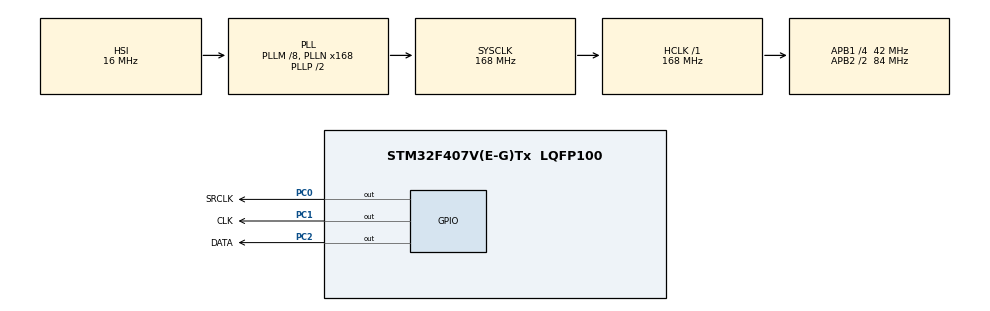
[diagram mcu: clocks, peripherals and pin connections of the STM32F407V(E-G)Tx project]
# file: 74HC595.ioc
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Mcu.Family=STM32F4
Mcu.Name=STM32F407V(E-G)Tx
Mcu.Package=LQFP100
NVIC.PriorityGroup=NVIC_PRIORITYGROUP_4
PA13.Mode=Serial_Wire
PA13.Signal=SYS_JTMS-SWDIO
PA14.Mode=Serial_Wire
PA14.Signal=SYS_JTCK-SWCLK
PC0.GPIO_Label=SRCLK
PC0.GPIO_Speed=GPIO_SPEED_FREQ_HIGH
PC0.Signal=GPIO_Output
PC1.GPIO_Label=CLK
PC1.GPIO_Speed=GPIO_SPEED_FREQ_HIGH
PC1.Signal=GPIO_Output
PC2.GPIO_Label=DATA
PC2.GPIO_Speed=GPIO_SPEED_FREQ_HIGH
PC2.Signal=GPIO_Output
PH0-OSC_IN.Mode=HSE-External-Oscillator
PH0-OSC_IN.Signal=RCC_OSC_IN
PH1-OSC_OUT.Mode=HSE-External-Oscillator
PH1-OSC_OUT.Signal=RCC_OSC_OUT
ProjectManager.HeapSize=0x200
ProjectManager.StackSize=0x400
ProjectManager.TargetToolchain=MDK-ARM V5
RCC.48MHZClocksFreq_Value=84000000
RCC.AHBFreq_Value=168000000
RCC.APB1CLKDivider=RCC_HCLK_DIV4
RCC.APB1Freq_Value=42000000
RCC.APB1TimFreq_Value=84000000
RCC.APB2CLKDivider=RCC_HCLK_DIV2
RCC.APB2Freq_Value=84000000
RCC.APB2TimFreq_Value=168000000
RCC.CortexFreq_Value=168000000
RCC.HCLKFreq_Value=168000000
RCC.HSE_VALUE=8000000
RCC.HSICalibrationValue=8
RCC.HSI_VALUE=16000000
RCC.LSE_VALUE=32768
RCC.PLLM=8
RCC.PLLN=168
RCC.SYSCLKFreq_VALUE=168000000
RCC.SYSCLKSource=RCC_SYSCLKSOURCE_PLLCLK
RCC.VCOOutputFreq_Value=336000000
board=custom

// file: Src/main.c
/* USER CODE BEGIN Header */
/**
  ******************************************************************************
  * @file           : main.c
  * @brief          : Main program body
  ******************************************************************************
  * @attention
  *
  * <h2><center>&copy; Copyright (c) 2019 STMicroelectronics.
  * All rights reserved.</center></h2>
  *
  * This software component is licensed by ST under BSD 3-Clause license,
  * the "License"; You may not use this file except in compliance with the
  * License. You may obtain a copy of the License at:
  *                        opensource.org/licenses/BSD-3-Clause
  *
  ******************************************************************************
  */
/* USER CODE END Header */

#include "main.h"

/* USER CODE BEGIN Includes */
#include "74hc595.h"
/* USER CODE END Includes */

void SystemClock_Config(void);
static void MX_GPIO_Init(void);

int main(void)
{
  /* USER CODE BEGIN 1 */
	int cnt = 0;
	int reverse = 0;
  /* USER CODE END 1 */

  /* MCU Configuration--------------------------------------------------------*/

  /* Reset of all peripherals, Initializes the Flash interface and the Systick. */
  HAL_Init();

  /* Configure the system clock */
  SystemClock_Config();

  /* Initialize all configured peripherals */
  MX_GPIO_Init();
  /* USER CODE BEGIN 2 */
			for(cnt = 0; cnt < 48; cnt++)
			{
				if(reverse == 0)
				{
					ShiftRegister74HC595_setPin(cnt, LOW);
					reverse = 1;
				}
				else
				{
					ShiftRegister74HC595_setPin(cnt, HIGH);
					reverse = 0;
				}
			}
	ShiftRegister74HC595_update();
  /* USER CODE END 2 */

  /* Infinite loop */
  while (1)
  {

//		ShiftRegister74HC595_setAll(LOW);
		HAL_Delay(3000);
//		ShiftRegister74HC595_setAll(HIGH);
//		HAL_Delay(3000);
  }
}

void SystemClock_Config(void)
{
  RCC_OscInitTypeDef RCC_OscInitStruct = {0};
  RCC_ClkInitTypeDef RCC_ClkInitStruct = {0};

  /** Configure the main internal regulator output voltage
  */
  __HAL_RCC_PWR_CLK_ENABLE();
  __HAL_PWR_VOLTAGESCALING_CONFIG(PWR_REGULATOR_VOLTAGE_SCALE1);
  /** Initializes the CPU, AHB and APB busses clocks
  */
  RCC_OscInitStruct.OscillatorType = RCC_OSCILLATORTYPE_HSI;
  RCC_OscInitStruct.HSIState = RCC_HSI_ON;
  RCC_OscInitStruct.HSICalibrationValue = 8;
  RCC_OscInitStruct.PLL.PLLState = RCC_PLL_ON;
  RCC_OscInitStruct.PLL.PLLSource = RCC_PLLSOURCE_HSI;
  RCC_OscInitStruct.PLL.PLLM = 8;
  RCC_OscInitStruct.PLL.PLLN = 168;
  RCC_OscInitStruct.PLL.PLLP = RCC_PLLP_DIV2;
  RCC_OscInitStruct.PLL.PLLQ = 4;
  if (HAL_RCC_OscConfig(&RCC_OscInitStruct) != HAL_OK)
  {
    Error_Handler();
  }
  /** Initializes the CPU, AHB and APB busses clocks
  */
  RCC_ClkInitStruct.ClockType = RCC_CLOCKTYPE_HCLK|RCC_CLOCKTYPE_SYSCLK
                              |RCC_CLOCKTYPE_PCLK1|RCC_CLOCKTYPE_PCLK2;
  RCC_ClkInitStruct.SYSCLKSource = RCC_SYSCLKSOURCE_PLLCLK;
  RCC_ClkInitStruct.AHBCLKDivider = RCC_SYSCLK_DIV1;
  RCC_ClkInitStruct.APB1CLKDivider = RCC_HCLK_DIV4;
  RCC_ClkInitStruct.APB2CLKDivider = RCC_HCLK_DIV2;

  if (HAL_RCC_ClockConfig(&RCC_ClkInitStruct, FLASH_LATENCY_5) != HAL_OK)
  {
    Error_Handler();
  }
}

static void MX_GPIO_Init(void)
{
  GPIO_InitTypeDef GPIO_InitStruct = {0};

  /* GPIO Ports Clock Enable */
  __HAL_RCC_GPIOH_CLK_ENABLE();
  __HAL_RCC_GPIOC_CLK_ENABLE();
  __HAL_RCC_GPIOA_CLK_ENABLE();

  /*Configure GPIO pin Output Level */
  HAL_GPIO_WritePin(GPIOC, CLK_Pin|SRCLK_Pin|DATA_Pin, GPIO_PIN_RESET);

  /*Configure GPIO pins : CLK_Pin SRCLK_Pin DATA_Pin */
  GPIO_InitStruct.Pin = CLK_Pin|SRCLK_Pin|DATA_Pin;
  GPIO_InitStruct.Mode = GPIO_MODE_OUTPUT_PP;
  GPIO_InitStruct.Pull = GPIO_NOPULL;
  GPIO_InitStruct.Speed = GPIO_SPEED_FREQ_HIGH;
  HAL_GPIO_Init(GPIOC, &GPIO_InitStruct);

}

void Error_Handler(void)
{
}

/************************ (C) COPYRIGHT STMicroelectronics *****END OF FILE****/
